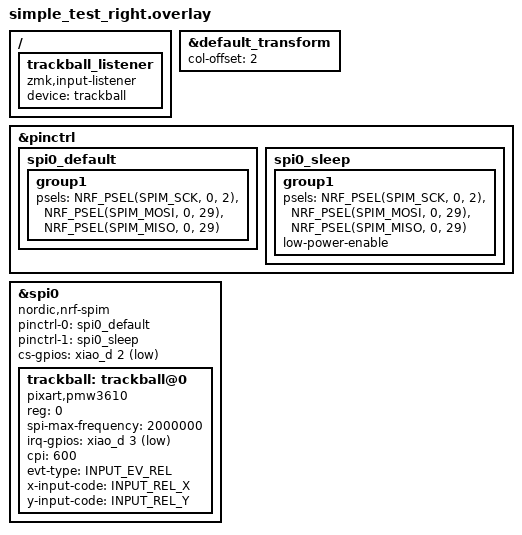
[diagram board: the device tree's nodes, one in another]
#include "simple_test.dtsi"
#include <zephyr/dt-bindings/input/input-event-codes.h>

&default_transform {
    col-offset = <2>;
};

&pinctrl {
    spi0_default: spi0_default {
        group1 {
            psels = <NRF_PSEL(SPIM_SCK, 0, 2)>,   // SCLK -> D0 (P0.02)
                    <NRF_PSEL(SPIM_MOSI, 0, 29)>, // SDIO -> D1 (P0.29)
                    <NRF_PSEL(SPIM_MISO, 0, 29)>; // SDIO -> D1 (P0.29, same pin)
        };
    };

    spi0_sleep: spi0_sleep {
        group1 {
            psels = <NRF_PSEL(SPIM_SCK, 0, 2)>,   // SCLK -> D0 (P0.02)
                    <NRF_PSEL(SPIM_MOSI, 0, 29)>, // SDIO -> D1 (P0.29)
                    <NRF_PSEL(SPIM_MISO, 0, 29)>; // SDIO -> D1 (P0.29, same pin)
            low-power-enable;
        };
    };
};

&spi0 {
    status = "okay";
    compatible = "nordic,nrf-spim";
    pinctrl-0 = <&spi0_default>;
    pinctrl-1 = <&spi0_sleep>;
    pinctrl-names = "default", "sleep";
    cs-gpios = <&xiao_d 2 GPIO_ACTIVE_LOW>;  // NCS -> D2

    trackball: trackball@0 {
        status = "okay";
        compatible = "pixart,pmw3610";
        reg = <0>;
        spi-max-frequency = <2000000>;
        irq-gpios = <&xiao_d 3 (GPIO_ACTIVE_LOW | GPIO_PULL_UP)>;  // MOT -> D3
        cpi = <600>;
        evt-type = <INPUT_EV_REL>;
        x-input-code = <INPUT_REL_X>;
        y-input-code = <INPUT_REL_Y>;
    };
};

/ {
    trackball_listener {
        compatible = "zmk,input-listener";
        device = <&trackball>;
    };
};
